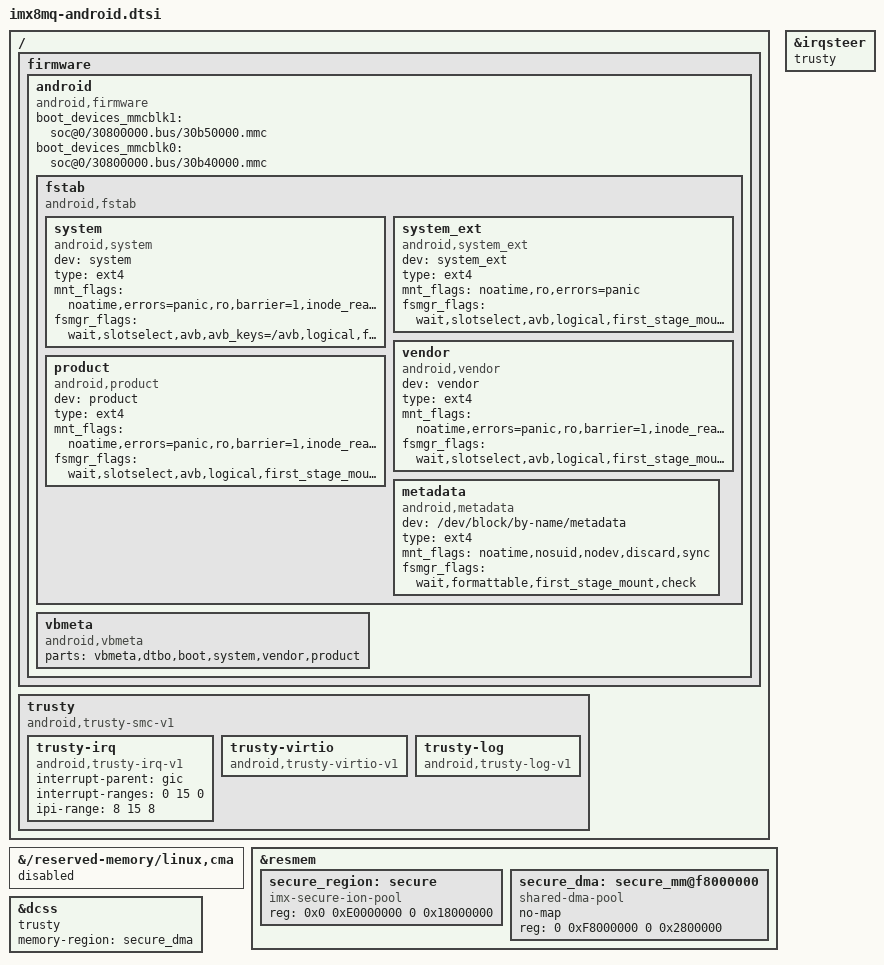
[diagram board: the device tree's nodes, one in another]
// SPDX-License-Identifier: (GPL-2.0+ OR MIT)
/*
 * Copyright 2022 NXP
 */

/ {
	firmware {
		android {
			compatible = "android,firmware";
			/* sd card node which used if androidboot.boot_device_root=mmcblk1 */
			boot_devices_mmcblk1 = "soc@0/30800000.bus/30b50000.mmc";
			/* emmc node which used if androidboot.boot_device_root=mmcblk0 */
			boot_devices_mmcblk0 = "soc@0/30800000.bus/30b40000.mmc";
			fstab {
				compatible = "android,fstab";
				system {
					compatible = "android,system";
					dev = "system";
					type = "ext4";
					mnt_flags = "noatime,errors=panic,ro,barrier=1,inode_readahead_blks=8";
					fsmgr_flags = "wait,slotselect,avb,avb_keys=/avb,logical,first_stage_mount";
				};
				system_ext {
					compatible = "android,system_ext";
					dev = "system_ext";
					type = "ext4";
					mnt_flags = "noatime,ro,errors=panic";
					fsmgr_flags = "wait,slotselect,avb,logical,first_stage_mount";
				};
				vendor {
					compatible = "android,vendor";
					dev = "vendor";
					type = "ext4";
					mnt_flags = "noatime,errors=panic,ro,barrier=1,inode_readahead_blks=8";
					fsmgr_flags = "wait,slotselect,avb,logical,first_stage_mount";
				};
				product {
					compatible = "android,product";
					dev = "product";
					type = "ext4";
					mnt_flags = "noatime,errors=panic,ro,barrier=1,inode_readahead_blks=8";
					fsmgr_flags = "wait,slotselect,avb,logical,first_stage_mount";
				};
				metadata {
					compatible = "android,metadata";
					dev = "/dev/block/by-name/metadata";
					type = "ext4";
					mnt_flags = "noatime,nosuid,nodev,discard,sync";
					fsmgr_flags = "wait,formattable,first_stage_mount,check";
				};
			};
			vbmeta {
				/*we need use FirstStageMountVBootV2 if we enable avb*/
				compatible = "android,vbmeta";
				/*parts means the partition witch can be mount in first stage*/
				parts = "vbmeta,dtbo,boot,system,vendor,product";
			};
		};
	};

	trusty {
		compatible = "android,trusty-smc-v1";
		ranges;
		#address-cells = <2>;
		#size-cells = <2>;
		trusty-irq {
			compatible = "android,trusty-irq-v1";
			interrupt-parent = <&gic>;
			interrupt-ranges = < 0 15 0>;
			ipi-range = <8 15 8>;
		};
		trusty-virtio {
			compatible = "android,trusty-virtio-v1";
		};
		trusty-log {
			compatible = "android,trusty-log-v1";
		};
	};
};

&{/reserved-memory/linux,cma} {
	status = "disabled";
};

&resmem {
	secure_region: secure {
		 compatible = "imx-secure-ion-pool";
		 reg = <0x0 0xE0000000 0 0x18000000>;
	};
	secure_dma: secure_mm@f8000000 {
		compatible = "shared-dma-pool";
		no-map;
		reg = <0 0xF8000000 0 0x2800000>;
	};
};

&dcss {
	trusty;
	memory-region = <&secure_dma>;
};

&irqsteer {
	trusty;
};
